# CH585SFR register map
Vendor: WCH Ltd.; Series: CH58x; File version: 1.1
CPU: RISC-V r0p0, little endian, no MPU, no FPU, 2 interrupt priority bits
Registers are 8-bit, read-write, reset 0x0 unless marked. A register's access mark holds for its fields unless they carry their own. Offsets are from the block's base; [hi:lo] are bit positions; {n}, {i} and the like mark numbered series.

## LCD
Base 0x40006000
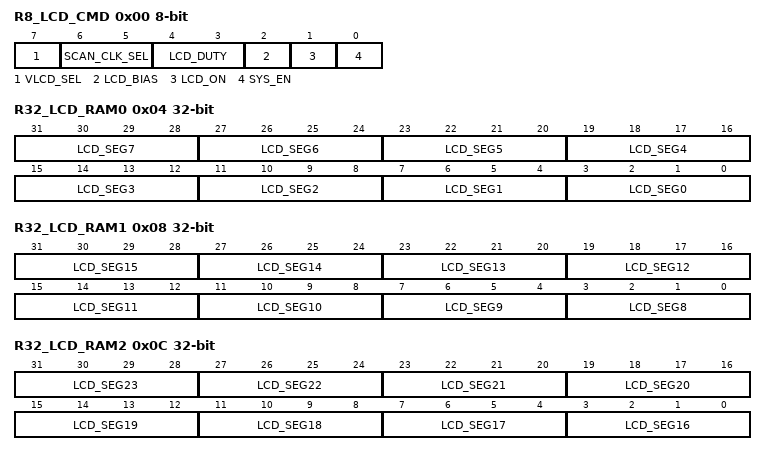
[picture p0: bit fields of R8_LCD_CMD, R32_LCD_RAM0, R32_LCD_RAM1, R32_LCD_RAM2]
0x00 R8_LCD_CMD — RW, LCD Command Register
  [7] VLCD_SEL — RW, LCD driver voltage selection
  [6:5] SCAN_CLK_SEL — RW, Scan clock selection
  [4:3] LCD_DUTY — RW, LCD duty cycle selection
  [2] LCD_BIAS — RW, PWM6 Bias ratio selection enable
  [1] LCD_ON — RW, LCD switch
  [0] SYS_EN — RW, System Enable
0x04 R32_LCD_RAM0 32-bit — RW, LCD RAM0 register
  [4n+3:4n] LCD_SEG{n} (n=0..7) — RW, SEG{n} segment data
0x08 R32_LCD_RAM1 32-bit — RW, LCD RAM1 register
  [4n-29:4n-32] LCD_SEG{n} (n=8..15) — RW, SEG{n} segment data
0x0C R32_LCD_RAM2 32-bit — RW, LCD RAM2 register
  [4n-61:4n-64] LCD_SEG{n} (n=16..23) — RW, SEG{n} segment data
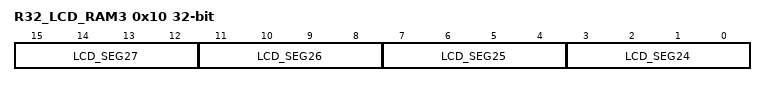
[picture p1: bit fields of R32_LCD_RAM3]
0x10 R32_LCD_RAM3 32-bit — RW, LCD RAM3 register
  [4n-93:4n-96] LCD_SEG{n} (n=24..27) — RW, SEG{n} segment data
0x14 R32_LCD_SEG_EN 32-bit — RW, LCD segment enable register
  [27:0] RB_LCD_SEG_EN — RW, Enable SEG0-SEG27 segment, high level effective

## LED
Base 0x4000F000
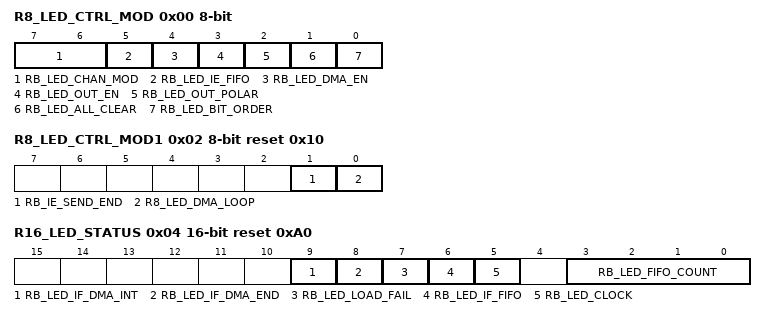
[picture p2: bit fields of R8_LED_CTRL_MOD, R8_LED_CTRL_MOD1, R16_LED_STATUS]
0x00 R8_LED_CTRL_MOD — RW, LED mode configuration register
  [7:6] RB_LED_CHAN_MOD — LED channel mode selection
  [5] RB_LED_IE_FIFO — FIFO count over half interrupt enabled
  [4] RB_LED_DMA_EN — LED DMA function and DMA interrupt enable
  [3] RB_LED_OUT_EN — LED signal output enable
  [2] RB_LED_OUT_POLAR — LED data output polarity control bit
  [1] RB_LED_ALL_CLEAR — LED FIFO/counter/interrupt flag reset to zero
  [0] RB_LED_BIT_ORDER — Selection of LED serial data bit sequence
0x01 R8_LED_CLOCK_DIV reset 0x10 — RW, LED serial clock divider register
  [7:0] R8_LED_CLOCK_DIV — LED output clock frequency division coefficient
0x02 R8_LED_CTRL_MOD1 reset 0x10 — RW, LED mode configuration register 1
  [1] RB_IE_SEND_END — DMA All Data Transfer End Interrupt Enable
  [0] R8_LED_DMA_LOOP — Enable LED DMA data cycling usage
0x04 R16_LED_STATUS 16-bit reset 0xA0 — RW1, LED status register
  [9] RB_LED_IF_DMA_INT — DMA transfer end interrupt flag bit
  [8] RB_LED_IF_DMA_END — DMA completion flag, write 1 to reset or write R16_SED-DMA_CNT to reset
  [7] RB_LED_LOAD_FAIL — Loading data results
  [6] RB_LED_IF_FIFO — FIFO count over half interrupt flag, write 1 to reset or write R16_SED_LFO to reset
  [5] RB_LED_CLOCK — Current LED clock signal level status
  [3:0] RB_LED_FIFO_COUNT — The byte count value in the current FIFO must be even
0x08 R32_LED_FIFO 32-bit wo reset not defined — WO, LED data FIFO register
  [31:0] R32_LED_FIFO — LED data FIFO input, 32-bit write
0x10 R16_LED_DMA_LEN 16-bit wo reset not defined — WO, LED DMA transmission length
  [11:0] R16_LED_DMA_LENGTH — DMA transmission count length
0x14 R16_LED_DMA_CNT 16-bit wo — WO, LED DMA remaining count register
  [11:0] RB_LED_DMA_CNT — LED_SMA_maIN Main Buffer Current DMA Remaining Words (16 bits) Count
0x18 R32_LED_DMA_BEG 32-bit reset not defined — RW, LED DMA starting address
  [16:2] RB_LED_DMA_BEG — DMA starting address
0x1C R32_LED_DMA_CUR 32-bit ro reset not defined — RO, LED DMA current address
  [16:2] RB_LED_DMA_CUR — LED DMA current address

## Systick
Base 0xE000F000
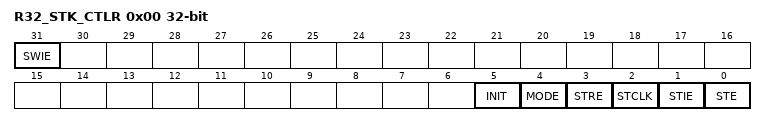
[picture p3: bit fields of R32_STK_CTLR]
0x00 R32_STK_CTLR 32-bit — Systick counter control register
  [31] SWIE — RW0,System soft interrupt enable
  [5] INIT — Initial counter value updated
  [4] MODE — counter mode
  [3] STRE — System counter reload control
  [2] STCLK — System counter clock Source selection
  [1] STIE — Systick counter interrupt enable
  [0] STE — Systick counter enable
0x04 R32_STK_SR 32-bit — Systick count status register
  [0] CNTIF — RW,CNTIF
0x08 R32_STK_CNTL 32-bit — Systick counter low register
  [31:0] CNTL — RW,CNTL
0x0C R32_STK_CNTH 32-bit — Systick counter high register
  [31:0] CNTH — RW,CNTH
0x10 R32_STK_CMPLR 32-bit — Systick compare low register
  [31:0] CMPL — RW,CMPL
0x14 R32_STK_CMPHR 32-bit — Systick compare high register
  [31:0] CMPH — RW,CMPH
